# STM32F417ZGT6 register map
File version: 1.0
Registers are 32-bit, access not given, reset 0x0 unless marked. A register's access mark holds for its fields unless they carry their own. Offsets are from the block's base; [hi:lo] are bit positions; {n}, {i} and the like mark numbered series.

## ADC123_COMMON
Base 0x40012300
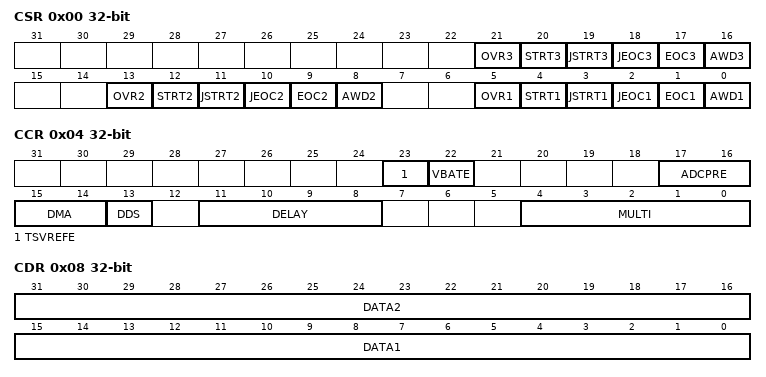
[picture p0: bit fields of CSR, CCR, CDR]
0x00 CSR
  [21] OVR3, [20] STRT3, [19] JSTRT3, [18] JEOC3, [17] EOC3, [16] AWD3, [13] OVR2, [12] STRT2, [11] JSTRT2, [10] JEOC2, [9] EOC2, [8] AWD2, [5] OVR1, [4] STRT1, [3] JSTRT1, [2] JEOC1, [1] EOC1, [0] AWD1
0x04 CCR
  [23] TSVREFE, [22] VBATE, [17:16] ADCPRE, [15:14] DMA, [13] DDS, [11:8] DELAY, [4:0] MULTI
0x08 CDR
  [31:16] DATA2, [15:0] DATA1

## SDIO
Base 0x40012C00
0x00 POWER
  [1:0] PWRCTRL
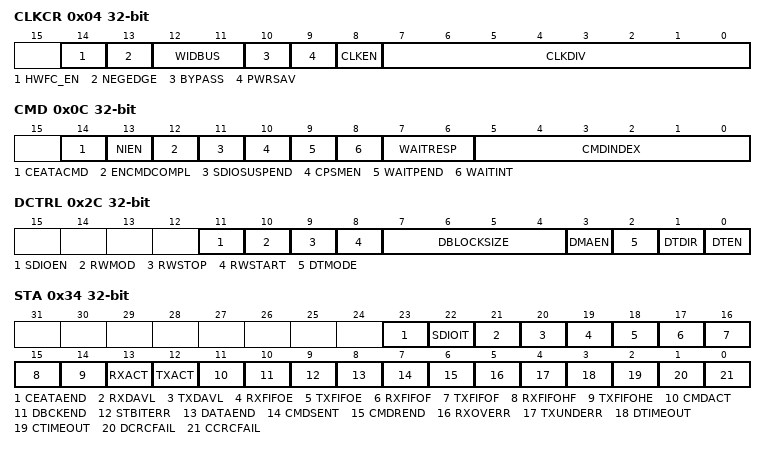
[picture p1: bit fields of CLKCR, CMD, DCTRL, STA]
0x04 CLKCR
  [14] HWFC_EN, [13] NEGEDGE, [12:11] WIDBUS, [10] BYPASS, [9] PWRSAV, [8] CLKEN, [7:0] CLKDIV
0x08 ARG
  [31:0] CMDARG
0x0C CMD
  [14] CEATACMD, [13] NIEN, [12] ENCMDCOMPL, [11] SDIOSUSPEND, [10] CPSMEN, [9] WAITPEND, [8] WAITINT, [7:6] WAITRESP, [5:0] CMDINDEX
0x10 RESPCMD
  [5:0] RESPCMD
{0x10+4i} RESP{i} (i=1..4)
  [31:0] CARDSTATUS{i}
0x24 DTIMER
  [31:0] DATATIME
0x28 DLEN
  [24:0] DATALENGTH
0x2C DCTRL
  [11] SDIOEN, [10] RWMOD, [9] RWSTOP, [8] RWSTART, [7:4] DBLOCKSIZE, [3] DMAEN, [2] DTMODE, [1] DTDIR, [0] DTEN
0x30 DCOUNT
  [24:0] DATACOUNT
0x34 STA
  [23] CEATAEND, [22] SDIOIT, [21] RXDAVL, [20] TXDAVL, [19] RXFIFOE, [18] TXFIFOE, [17] RXFIFOF, [16] TXFIFOF, [15] RXFIFOHF, [14] TXFIFOHE, [13] RXACT, [12] TXACT, [11] CMDACT, [10] DBCKEND, [9] STBITERR, [8] DATAEND, [7] CMDSENT, [6] CMDREND, [5] RXOVERR, [4] TXUNDERR, [3] DTIMEOUT, [2] CTIMEOUT, [1] DCRCFAIL, [0] CCRCFAIL
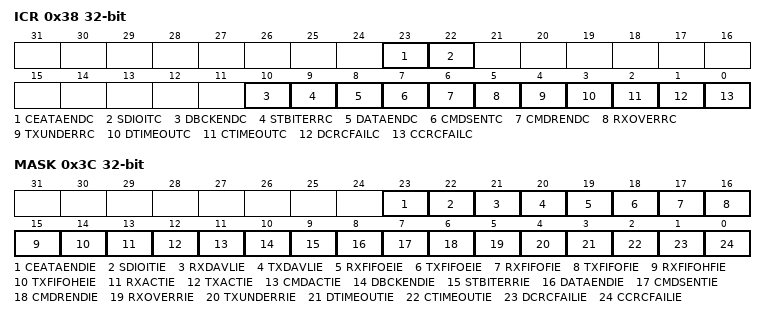
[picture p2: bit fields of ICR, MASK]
0x38 ICR
  [23] CEATAENDC, [22] SDIOITC, [10] DBCKENDC, [9] STBITERRC, [8] DATAENDC, [7] CMDSENTC, [6] CMDRENDC, [5] RXOVERRC, [4] TXUNDERRC, [3] DTIMEOUTC, [2] CTIMEOUTC, [1] DCRCFAILC, [0] CCRCFAILC
0x3C MASK
  [23] CEATAENDIE, [22] SDIOITIE, [21] RXDAVLIE, [20] TXDAVLIE, [19] RXFIFOEIE, [18] TXFIFOEIE, [17] RXFIFOFIE, [16] TXFIFOFIE, [15] RXFIFOHFIE, [14] TXFIFOHEIE, [13] RXACTIE, [12] TXACTIE, [11] CMDACTIE, [10] DBCKENDIE, [9] STBITERRIE, [8] DATAENDIE, [7] CMDSENTIE, [6] CMDRENDIE, [5] RXOVERRIE, [4] TXUNDERRIE, [3] DTIMEOUTIE, [2] CTIMEOUTIE, [1] DCRCFAILIE, [0] CCRCFAILIE
0x48 FIFOCNT
  [23:0] FIFOCOUNT
0x80 FIFO
  [31:0] FIFODATA

## SYSCFG
Base 0x40013800
0x00 MEMRMP
  [1:0] MEM_MODE
0x04 PMC
  [23] MII_RMII_SEL
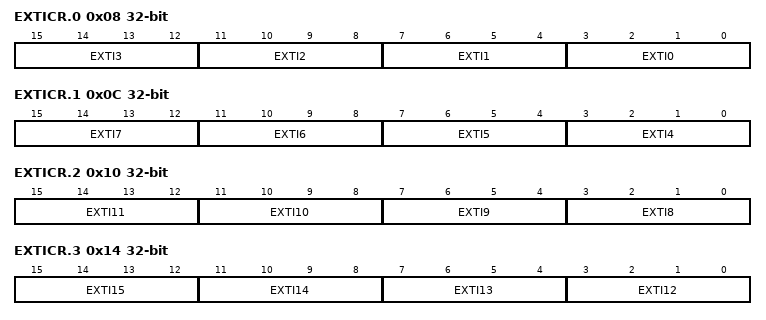
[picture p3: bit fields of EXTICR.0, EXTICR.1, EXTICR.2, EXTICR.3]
0x08 EXTICR.0
  [4n+3:4n] EXTI{n} (n=0..3)
0x0C EXTICR.1
  [4n-13:4n-16] EXTI{n} (n=4..7)
0x10 EXTICR.2
  [4n-29:4n-32] EXTI{n} (n=8..11)
0x14 EXTICR.3
  [4n-45:4n-48] EXTI{n} (n=12..15)
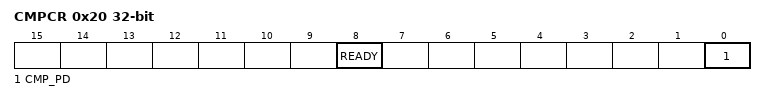
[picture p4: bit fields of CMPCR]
0x20 CMPCR
  [8] READY, [0] CMP_PD

## EXTI
Base 0x40013C00
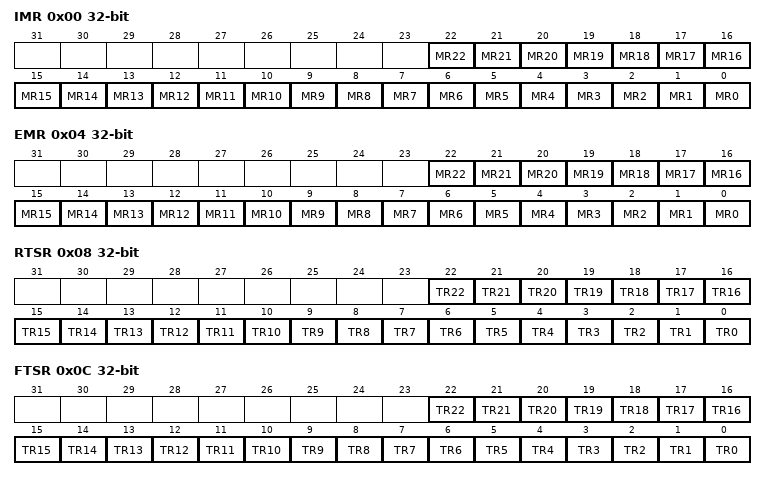
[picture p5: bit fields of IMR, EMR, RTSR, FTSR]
0x00 IMR
  [n] MR{n} (n=0..22)
0x04 EMR
  [n] MR{n} (n=0..22)
0x08 RTSR
  [n] TR{n} (n=0..22)
0x0C FTSR
  [n] TR{n} (n=0..22)
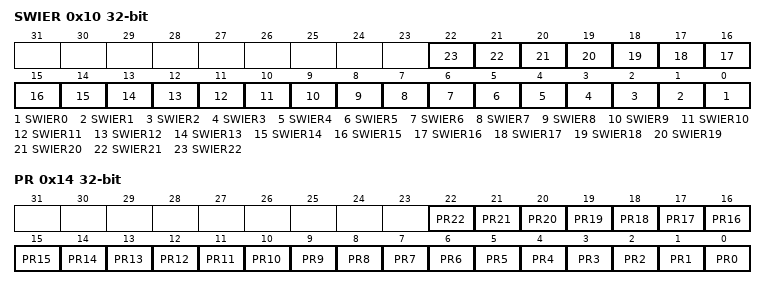
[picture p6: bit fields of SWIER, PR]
0x10 SWIER
  [n] SWIER{n} (n=0..22)
0x14 PR
  [n] PR{n} (n=0..22)

## GPIOA
Base 0x40020000
Same registers: GPIOB 0x40020400, GPIOC 0x40020800, GPIOD 0x40020C00, GPIOE 0x40021000, GPIOF 0x40021400, GPIOG 0x40021800, GPIOH 0x40021C00, GPIOI 0x40022000
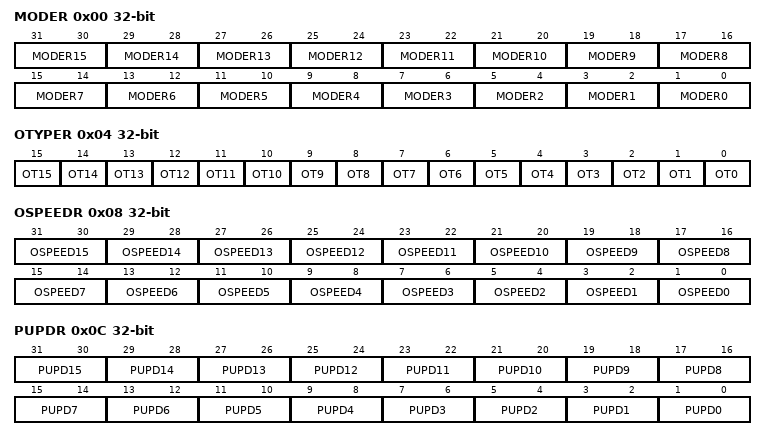
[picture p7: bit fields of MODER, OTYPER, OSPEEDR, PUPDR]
0x00 MODER
  [2n+1:2n] MODER{n} (n=0..15)
0x04 OTYPER
  [n] OT{n} (n=0..15)
0x08 OSPEEDR
  [2n+1:2n] OSPEED{n} (n=0..15)
0x0C PUPDR
  [2n+1:2n] PUPD{n} (n=0..15)
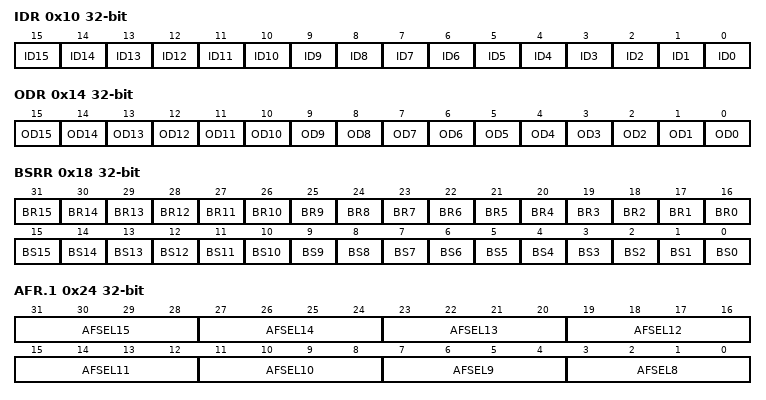
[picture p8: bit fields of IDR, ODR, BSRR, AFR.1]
0x10 IDR
  [n] ID{n} (n=0..15)
0x14 ODR
  [n] OD{n} (n=0..15)
0x18 BSRR
  [n+16] BR{n} (n=0..15), [n] BS{n} (n=0..15)
0x1C LCKR
0x20 AFR.0
0x24 AFR.1
  [4n-29:4n-32] AFSEL{n} (n=8..15)

## CRC
Base 0x40023000
0x00 DR
0x04 IDR 8-bit
0x08 CR
  [0] RESET

## FLASH
Base 0x40023C00
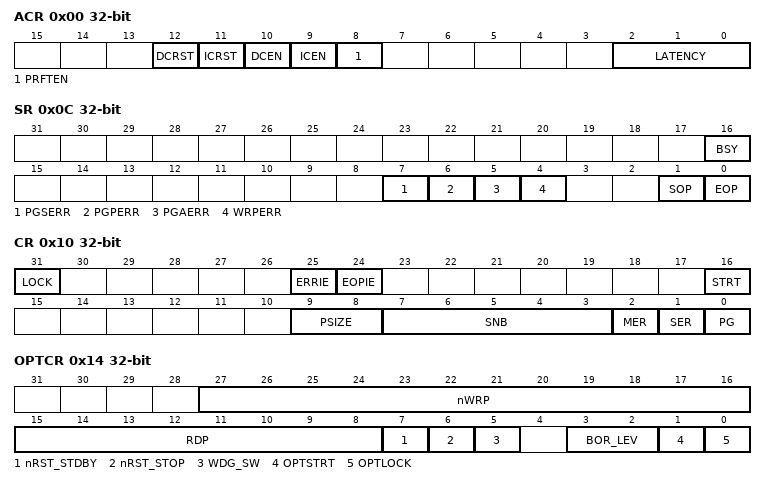
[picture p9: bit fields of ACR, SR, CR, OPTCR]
0x00 ACR
  [12] DCRST, [11] ICRST, [10] DCEN, [9] ICEN, [8] PRFTEN, [2:0] LATENCY
0x04 KEYR
0x08 OPTKEYR
0x0C SR
  [16] BSY, [7] PGSERR, [6] PGPERR, [5] PGAERR, [4] WRPERR, [1] SOP, [0] EOP
0x10 CR
  [31] LOCK, [25] ERRIE, [24] EOPIE, [16] STRT, [9:8] PSIZE, [7:3] SNB, [2] MER, [1] SER, [0] PG
0x14 OPTCR
  [27:16] nWRP, [15:8] RDP, [7] nRST_STDBY, [6] nRST_STOP, [5] WDG_SW, [3:2] BOR_LEV, [1] OPTSTRT, [0] OPTLOCK
0x18 OPTCR1
  [27:16] nWRP
